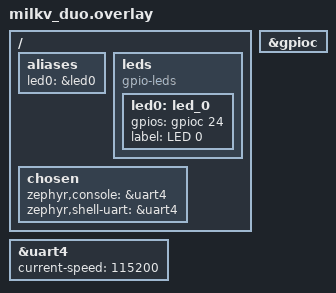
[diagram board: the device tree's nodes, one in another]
/ {
	aliases {
		led0 = &led0;
	};

	leds {
		compatible = "gpio-leds";
		led0: led_0 {
			gpios = <&gpioc 24 0>;
			label = "LED 0";
		};
        };

        chosen {
                zephyr,console = &uart4;
                zephyr,shell-uart = &uart4;
        };
};

&uart4 {
        status = "okay";
        current-speed = <115200>;
};

&gpioc {
	status = "okay";
};
